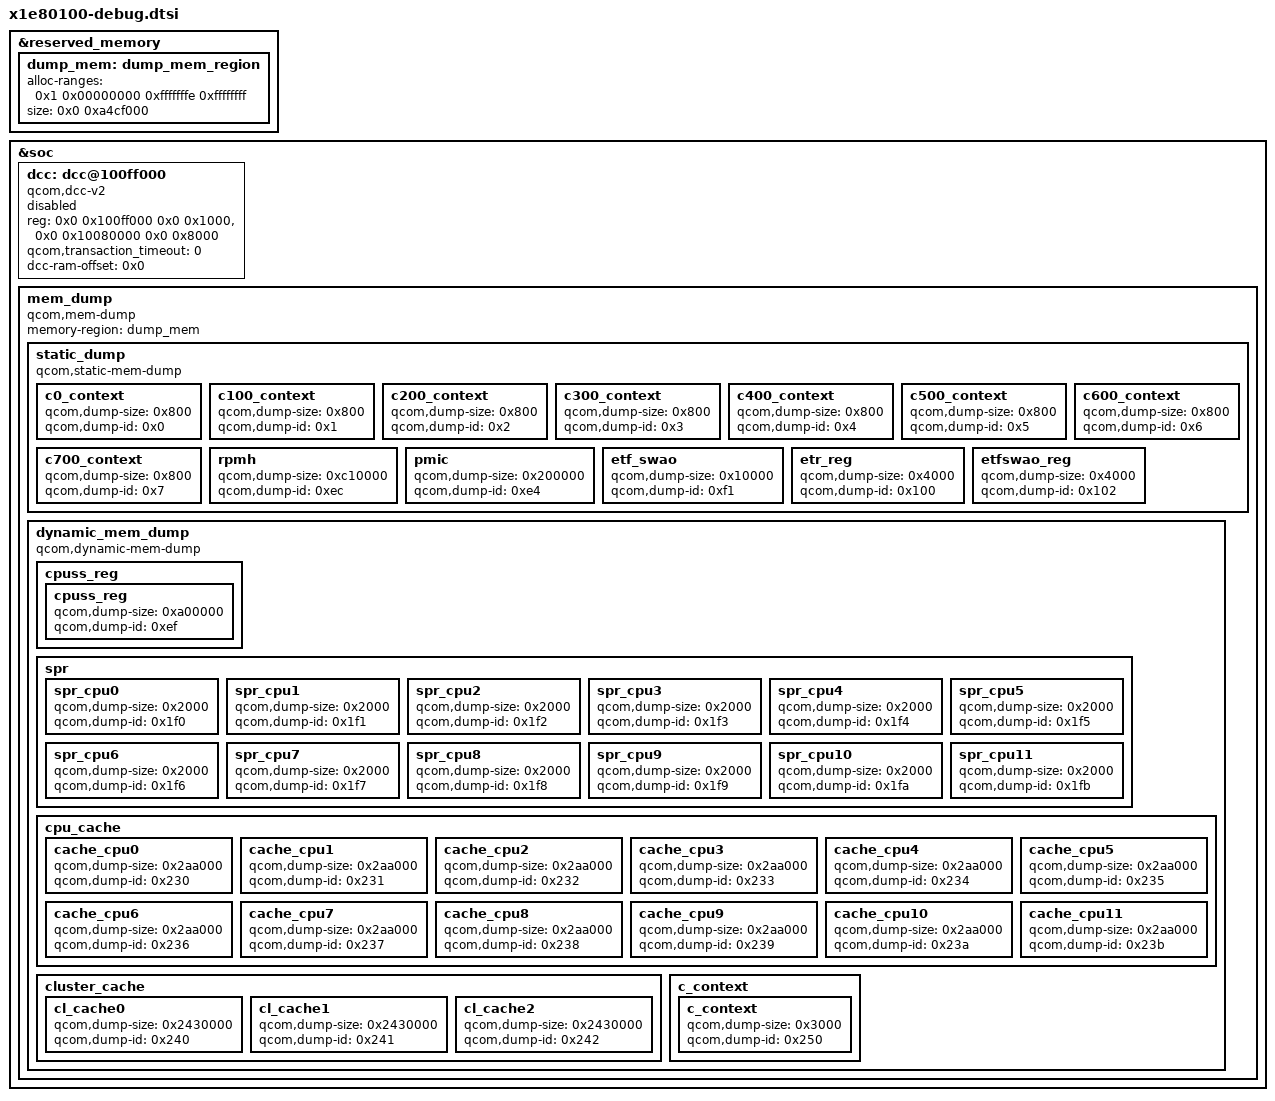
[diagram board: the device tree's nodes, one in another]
// SPDX-License-Identifier: BSD-3-Clause
/*
 * Copyright (c) Qualcomm Technologies, Inc. and/or its subsidiaries.
 */

#include <dt-bindings/soc/qcom,dcc_v2.h>

&reserved_memory {
	#address-cells = <2>;
	#size-cells = <2>;
	ranges;

	dump_mem: dump_mem_region {
		alloc-ranges = <0x1 0x00000000 0xfffffffe 0xffffffff>;
		size = <0x0 0xa4cf000>;
	};
};

&soc {
	dcc: dcc@100ff000 {
		compatible = "qcom,dcc-v2";
		reg = <0x0 0x100ff000 0x0 0x1000>,
		      <0x0 0x10080000 0x0 0x8000>;
		reg-names = "dcc-base", "dcc-ram-base";
		status = "disabled";

		qcom,transaction_timeout = <0>;
		dcc-ram-offset = <0x0>;
	};

	mem_dump {
		compatible = "qcom,mem-dump";
		memory-region = <&dump_mem>;

		static_dump {
			qcom,static-mem-dump;

			c0_context {
				qcom,dump-size = <0x800>;
				qcom,dump-id = <0x0>;
			};

			c100_context {
				qcom,dump-size = <0x800>;
				qcom,dump-id = <0x1>;
			};

			c200_context {
				qcom,dump-size = <0x800>;
				qcom,dump-id = <0x2>;
			};

			c300_context {
				qcom,dump-size = <0x800>;
				qcom,dump-id = <0x3>;
			};

			c400_context {
				qcom,dump-size = <0x800>;
				qcom,dump-id = <0x4>;
			};

			c500_context {
				qcom,dump-size = <0x800>;
				qcom,dump-id = <0x5>;
			};

			c600_context {
				qcom,dump-size = <0x800>;
				qcom,dump-id = <0x6>;
			};

			c700_context {
				qcom,dump-size = <0x800>;
				qcom,dump-id = <0x7>;
			};

			rpmh {
				qcom,dump-size = <0xc10000>;
				qcom,dump-id = <0xec>;
			};

			pmic {
				qcom,dump-size = <0x200000>;
				qcom,dump-id = <0xe4>;
			};

			etf_swao {
				qcom,dump-size = <0x10000>;
				qcom,dump-id = <0xf1>;
			};

			etr_reg {
				qcom,dump-size = <0x4000>;
				qcom,dump-id = <0x100>;
			};

			etfswao_reg {
				qcom,dump-size = <0x4000>;
				qcom,dump-id = <0x102>;
			};

		};

		dynamic_mem_dump {
			qcom,dynamic-mem-dump;

			cpuss_reg {
				cpuss_reg {
					qcom,dump-size = <0xa00000>;
					qcom,dump-id = <0xef>;
				};
			};

			spr {
				spr_cpu0 {
					qcom,dump-size = <0x2000>;
					qcom,dump-id = <0x1f0>;
				};

				spr_cpu1 {
					qcom,dump-size = <0x2000>;
					qcom,dump-id = <0x1f1>;
				};

				spr_cpu2 {
					qcom,dump-size = <0x2000>;
					qcom,dump-id = <0x1f2>;
				};

				spr_cpu3 {
					qcom,dump-size = <0x2000>;
					qcom,dump-id = <0x1f3>;
				};

				spr_cpu4 {
					qcom,dump-size = <0x2000>;
					qcom,dump-id = <0x1f4>;
				};

				spr_cpu5 {
					qcom,dump-size = <0x2000>;
					qcom,dump-id = <0x1f5>;
				};

				spr_cpu6 {
					qcom,dump-size = <0x2000>;
					qcom,dump-id = <0x1f6>;
				};

				spr_cpu7 {
					qcom,dump-size = <0x2000>;
					qcom,dump-id = <0x1f7>;
				};

				spr_cpu8 {
					qcom,dump-size = <0x2000>;
					qcom,dump-id = <0x1f8>;
				};

				spr_cpu9 {
					qcom,dump-size = <0x2000>;
					qcom,dump-id = <0x1f9>;
				};

				spr_cpu10 {
					qcom,dump-size = <0x2000>;
					qcom,dump-id = <0x1fa>;
				};

				spr_cpu11 {
					qcom,dump-size = <0x2000>;
					qcom,dump-id = <0x1fb>;
				};
			};

			cpu_cache {
				cache_cpu0 {
					qcom,dump-size = <0x2aa000>;
					qcom,dump-id = <0x230>;
				};

				cache_cpu1 {
					qcom,dump-size = <0x2aa000>;
					qcom,dump-id = <0x231>;
				};

				cache_cpu2 {
					qcom,dump-size = <0x2aa000>;
					qcom,dump-id = <0x232>;
				};

				cache_cpu3 {
					qcom,dump-size = <0x2aa000>;
					qcom,dump-id = <0x233>;
				};

				cache_cpu4 {
					qcom,dump-size = <0x2aa000>;
					qcom,dump-id = <0x234>;
				};

				cache_cpu5 {
					qcom,dump-size = <0x2aa000>;
					qcom,dump-id = <0x235>;
				};

				cache_cpu6 {
					qcom,dump-size = <0x2aa000>;
					qcom,dump-id = <0x236>;
				};

				cache_cpu7 {
					qcom,dump-size = <0x2aa000>;
					qcom,dump-id = <0x237>;
				};

				cache_cpu8 {
					qcom,dump-size = <0x2aa000>;
					qcom,dump-id = <0x238>;
				};

				cache_cpu9 {
					qcom,dump-size = <0x2aa000>;
					qcom,dump-id = <0x239>;
				};

				cache_cpu10 {
					qcom,dump-size = <0x2aa000>;
					qcom,dump-id = <0x23a>;
				};

				cache_cpu11 {
					qcom,dump-size = <0x2aa000>;
					qcom,dump-id = <0x23b>;
				};
			};

			cluster_cache {
				cl_cache0 {
					qcom,dump-size = <0x2430000>;
					qcom,dump-id = <0x240>;
				};

				cl_cache1 {
					qcom,dump-size = <0x2430000>;
					qcom,dump-id = <0x241>;
				};

				cl_cache2 {
					qcom,dump-size = <0x2430000>;
					qcom,dump-id = <0x242>;
				};
			};

			c_context {
				c_context {
					qcom,dump-size = <0x3000>;
					qcom,dump-id = <0x250>;
				};
			};
		};
	};
};
